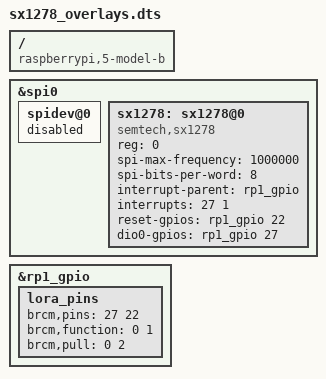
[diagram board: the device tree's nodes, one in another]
/dts-v1/;
/plugin/;

/ {
    compatible = "raspberrypi,5-model-b", "brcm,bcm2712";

    fragment@0 {
        target = <&spi0>;
        __overlay__ {
            status = "okay";
            #address-cells = <1>;
            #size-cells = <0>;

            spidev@0 {
                status = "disabled";
            };

            sx1278: sx1278@0 {
                compatible = "semtech,sx1278";
                reg = <0>; /* CE0 */
                spi-max-frequency = <1000000>;
                spi-bits-per-word = <8>;

                interrupt-parent = <&rp1_gpio>;
                interrupts = <27 1>; /* IRQ_TYPE_EDGE_RISING */

                reset-gpios = <&rp1_gpio 22 0>; /* GPIO_ACTIVE_HIGH */
                dio0-gpios = <&rp1_gpio 27 0>;  /* GPIO_ACTIVE_HIGH */

                status = "okay";
            };
        };
    };

    fragment@1 {
        target = <&rp1_gpio>;
        __overlay__ {
            lora_pins: lora_pins {
                brcm,pins = <27 22>;
                brcm,function = <0 1>; /* 27: in (0), 22: out (1) */
                brcm,pull = <0 2>;     /* 27 no pull, 13 Pull-up (2) */
            };
        };
    };
};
